# NPCX498S register map
File version: 1.0
Registers are 8-bit, read-write, reset 0x0 unless marked. A register's access mark holds for its fields unless they carry their own. Offsets are from the block's base; [hi:lo] are bit positions; {n}, {i} and the like mark numbered series; 'fields as' and 'values as' point back to an identical list.

## FIU_0
Base 0x40020000
Same registers: FIU_1 0x40021000
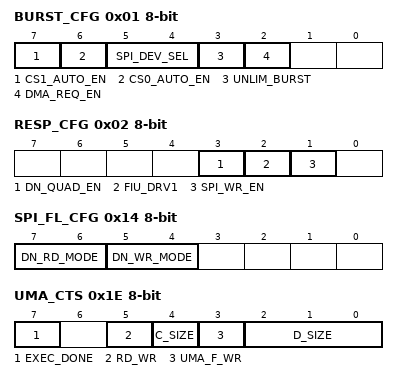
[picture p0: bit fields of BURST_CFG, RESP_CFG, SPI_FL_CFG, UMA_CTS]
0x01 BURST_CFG — Burst Configuration Register (BURST_CFG)
  [7] CS1_AUTO_EN — F_CS1 Auto-Assertion Enable
  [6] CS0_AUTO_EN — F_CS0 Auto-Assertion Enable
  [5:4] SPI_DEV_SEL — SPI Device Select
  [3] UNLIM_BURST — Unlimited Burst
  [2] DMA_REQ_EN — DMA Request Enable
0x02 RESP_CFG — FIU Response Configuration Register (RESP_CFG)
  [3] DN_QUAD_EN — Device 'n' Quad Enable
  [2] FIU_DRV1 — FIU IO2, IO3 Drive High
  [1] SPI_WR_EN — SPI Write Enable
0x14 SPI_FL_CFG — SPI Flash Configuration Register (SPI_FL_CFG)
  [7:6] DN_RD_MODE — Device 'n' Read Mode Select
  [5:4] DN_WR_MODE — Device 'n' Write Mode Select
0x16 UMA_CODE — UMA Code Byte Register (UMA_CODE)
{0x3+i} UMA_AB0-{i} (i=20..22) — UMA Address Byte 0-2 Register (UMA_AB0-2)
0x1A UMA_DB0-30 — UMA Data Byte 0-3 Register (UMA_DB0-3)
0x1B UMA_DB0-31 — UMA Data Byte 0-3 Register (UMA_DB0-3)
0x1C UMA_DB0-32 — UMA Data Byte 0-3 Register (UMA_DB0-3)
0x1D UMA_DB0-33 — UMA Data Byte 0-3 Register (UMA_DB0-3)
0x1E UMA_CTS — UMA Control and Status Register (UMA_CTS)
  [7] EXEC_DONE — Operation Execute/Done
  [5] RD_WR — Read/Write Select
  [4] C_SIZE — Code Field Size Select
  [3] UMA_F_WR — UMA Fast Write
  [2:0] D_SIZE — Data Field Size Select
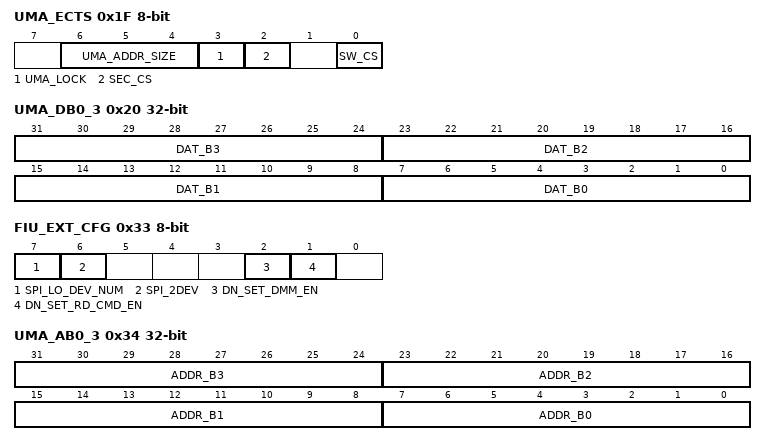
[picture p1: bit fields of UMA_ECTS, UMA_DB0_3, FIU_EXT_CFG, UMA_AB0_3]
0x1F UMA_ECTS — UMA Extended Control and Status Register (UMA_ECTS)
  [6:4] UMA_ADDR_SIZE — Address Field Size Select
  [3] UMA_LOCK — UMA Operation Lock
  [2] SEC_CS — Secondary Chip-Select
  [0] SW_CS — Software-Controlled Chip-Select
0x20 UMA_DB0_3 32-bit (reset mask 0xFF) — UMA Data Bytes 0-3 Register (UMA_DB0_3)
  [8n+7:8n] DAT_B{n} (n=0..3) — Data Byte {n}
0x25 UMA_DMM — UMA Dummy Register (UMA_DMM)
  [5:0] DMCSIZ — Dummy Cycles Size
0x30 Dn_FIU_RD_CMD — Device 'n' FIU Read Command Register (Dn_FIU_RD_CMD)
0x31 Dn_FIU_WR_CMD — Device 'n' FIU Write Command Register (Dn_FIU_WR_CMD)
0x32 Dn_FIU_DMM_CYC — Device 'n' FIU Dummy Cycle Register (Dn_FIU_DMM_CYC)
  [4:0] DN_DMM_CYC_NUM — Device 'n' Dummy Cycles Number
0x33 FIU_EXT_CFG — FIU Extended Configuration Register (FIU_EXT_CFG)
  [7] SPI_LO_DEV_NUM — SPI0 Low Device Number
  [6] SPI_2DEV — SPI Bus, Two Devices Enable
  [2] DN_SET_DMM_EN — Device 'n' Set Dummy Enable
  [1] DN_SET_RD_CMD_EN — Device 'n' Set Read Command Enable
0x34 UMA_AB0_3 32-bit (reset mask 0xFF) — UMA Address Byte 0_3 Register (UMA_AB0_3)
  [8n+7:8n] ADDR_B{n} (n=0..3) — Address Byte {n}
0x3C SPI_DEV — SPI Device Register (SPI_DEV)
  [7:5] DN_NADDRB — Device 'n' Number of Address Bytes
0x3E Dn_SPI_DEV_SIZE — Device 'n' SPI Device Size Register (Dn_SPI_DEV_SIZE)

## GDMA1
Base 0x40011000
Same registers: GDMA2 0x40011A00
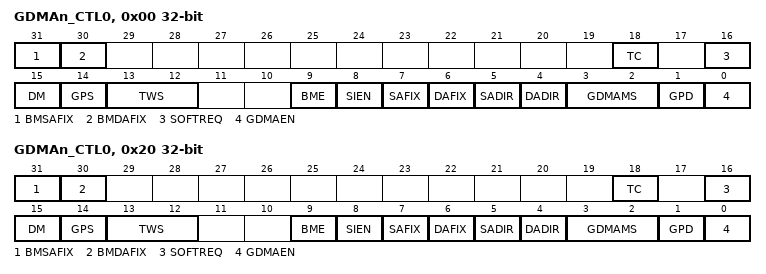
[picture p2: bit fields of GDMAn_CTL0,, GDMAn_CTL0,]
0x00 GDMAn_CTL0, GDMAn_CTL10 32-bit (reset mask 0xFF) — Channel 0/1 Control Register (GDMAn_CTL0, GDMAn_CTL1)
  [31] BMSAFIX — Burst Mode Source Address Fixed
  [30] BMDAFIX — Burst Mode Destination Address Fixed
  [18] TC — Terminal Count
  [16] SOFTREQ — Software Triggered GDMA Request
  [15] DM — Demand Mode
  [14] GPS — GDMA Power Save
  [13:12] TWS — Transfer Width Select
  [9] BME — Burst Mode Enable
  [8] SIEN — Stop Interrupt Enable
  [7] SAFIX — Source Address Fixed
  [6] DAFIX — Destination Address Fixed
  [5] SADIR — Source Address Direction
  [4] DADIR — Destination Address Direction
  [3:2] GDMAMS — GDMA Mode Select
  [1] GPD — GDMA Power-Down
  [0] GDMAEN — GDMA Enable
0x04 GDMAn_SRCB0, GDMAn_SRCB10 32-bit (reset mask 0xFF) — Channel 0/1 Source Base Address Register (GDMAn_SRCB0, GDMAn_SRCB1)
0x08 GDMAn_DSTB0, GDMAn_DSTB10 32-bit (reset mask 0xFF) — Channel 0/1 Destination Base Address Register (GDMAn_DSTB0, GDMAn_DSTB1)
0x0C GDMAn_TCNT0, GDMAn_TCNT10 32-bit (reset mask 0xFF) — Channel 0/1 Transfer Count Register (GDMAn_TCNT0, GDMAn_TCNT1)
  [23:0] TFR_CNT — 24-bit Transfer Count
0x10 GDMAn_CSRC0, GDMAn_CSRC10 32-bit (reset mask 0xFF) — Channel 0/1 Current Source Register (GDMAn_CSRC0, GDMAn_CSRC1)
0x14 GDMAn_CDST0, GDMAn_CDST10 32-bit (reset mask 0xFF) — Channel 0/1 Current Destination Register (GDMAn_CDST0, GDMAn_CDST1)
0x18 GDMAn_CTCNT0, GDMAn_CTCNT10 32-bit (reset mask 0xFF) — Channel 0/1 Current Transfer Count Register (GDMAn_CTCNT0, GDMAn_CTCNT1)
  [23:0] CURENT_TFR_CNT — Current Transfer Count
0x1C GDMAn_REQ_SL0, GDMAn_REQ_SL10 32-bit (reset mask 0xFF) — Channel 0/1 GDMA Request Select Register (GDMAn_REQ_SL0, GDMAn_REQ_SL1)
  [15:0] DREQ_SL — DMA Request Select
0x20 GDMAn_CTL0, GDMAn_CTL11 32-bit (reset mask 0xFF) — Channel 0/1 Control Register (GDMAn_CTL0, GDMAn_CTL1)
  fields as GDMAn_CTL0,
0x24 GDMAn_SRCB0, GDMAn_SRCB11 32-bit (reset mask 0xFF) — Channel 0/1 Source Base Address Register (GDMAn_SRCB0, GDMAn_SRCB1)
0x28 GDMAn_DSTB0, GDMAn_DSTB11 32-bit (reset mask 0xFF) — Channel 0/1 Destination Base Address Register (GDMAn_DSTB0, GDMAn_DSTB1)
0x2C GDMAn_TCNT0, GDMAn_TCNT11 32-bit (reset mask 0xFF) — Channel 0/1 Transfer Count Register (GDMAn_TCNT0, GDMAn_TCNT1)
  [23:0] TFR_CNT — 24-bit Transfer Count
0x30 GDMAn_CSRC0, GDMAn_CSRC11 32-bit (reset mask 0xFF) — Channel 0/1 Current Source Register (GDMAn_CSRC0, GDMAn_CSRC1)
0x34 GDMAn_CDST0, GDMAn_CDST11 32-bit (reset mask 0xFF) — Channel 0/1 Current Destination Register (GDMAn_CDST0, GDMAn_CDST1)
0x38 GDMAn_CTCNT0, GDMAn_CTCNT11 32-bit (reset mask 0xFF) — Channel 0/1 Current Transfer Count Register (GDMAn_CTCNT0, GDMAn_CTCNT1)
  [23:0] CURENT_TFR_CNT — Current Transfer Count
0x3C GDMAn_REQ_SL0, GDMAn_REQ_SL11 32-bit (reset mask 0xFF) — Channel 0/1 GDMA Request Select Register (GDMAn_REQ_SL0, GDMAn_REQ_SL1)
  [15:0] DREQ_SL — DMA Request Select
